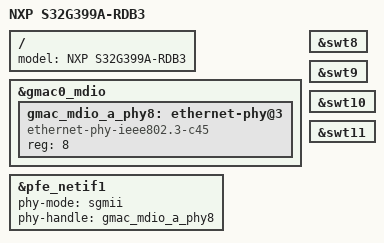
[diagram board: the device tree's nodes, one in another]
// SPDX-License-Identifier: GPL-2.0-or-later
/*
 * Device Tree file for S32G399ARDB3 Board Rev E.
 *
 * Copyright 2022 NXP
 *
 */

/dts-v1/;
#include "fsl-s32g3.dtsi"
#include "fsl-s32gxxxa-rdb.dtsi"
/ {
	model = "NXP S32G399A-RDB3";
};

&gmac0_mdio {
	/* AQR113C */
	gmac_mdio_a_phy8: ethernet-phy@3 {
		compatible = "ethernet-phy-ieee802.3-c45";
		#address-cells = <1>;
		#size-cells = <0>;
		reg = <8>;
	};
};

&pfe_netif1 {
	phy-mode = "sgmii";
	phy-handle = <&gmac_mdio_a_phy8>;
};

&swt8 {
	status = "okay";
};

&swt9 {
	status = "okay";
};

&swt10 {
	status = "okay";
};

&swt11 {
	status = "okay";
};
